# MCU_ARMSS_CCMR5 register map
Vendor: Texas Instruments
Peripheral module from a debugger description file (folder am65x).
Registers are 32-bit, read-write, reset 0x0 unless marked. A register's access mark holds for its fields unless they carry their own. Offsets are as the file gives them; lines under a group give offsets from that group; [hi:lo] are bit positions; {n}, {i} and the like mark numbered series; 'fields as' and 'values as' point back to an identical list; <NAME> marks a mode.

## MCU_ARMSS_CCMR5
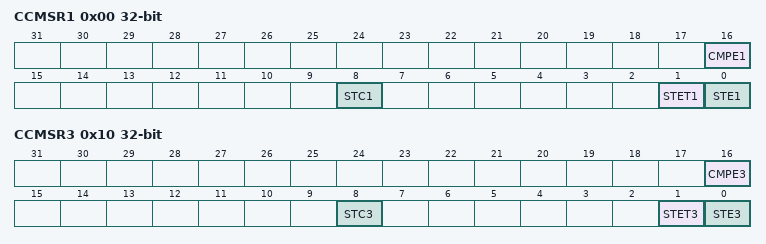
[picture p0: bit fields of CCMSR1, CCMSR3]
0x00 CCMSR1 — Shows the Error and Self test Status of the CPU CPU Compare block.
  [16] CMPE1 — This is the CMPE1 field
  [8] STC1 — This is the STC1 field
  [1] STET1 — This is the STET1 field
  [0] STE1 — This is the STE1 field
0x04 CCMKEYR1 — Selects Operating mode of CPU Compare block.
  [3:0] MKEY1 — This is the MKEY1 field
0x10 CCMSR3 — Shows the Error and Self test Status of the CPU CPU Compare block.
  [16] CMPE3 — This is the CMPE3 field
  [8] STC3 — This is the STC3 field
  [1] STET3 — This is the STET3 field
  [0] STE3 — This is the STE3 field
0x14 CCMKEYR3 — Selects Operating mode of CPU Compare block.
  [3:0] MKEY3 — This is the MKEY3 field
0x18 CCMPOLCNTRL — Selects Operating mode of CPU Compare block.
  [7:0] POL_INV — This is the Polarity Inversion field
